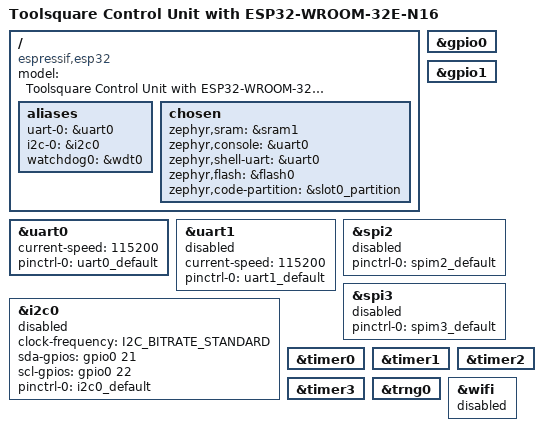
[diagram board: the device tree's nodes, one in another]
/dts-v1/;

#include <espressif/esp32/esp32_wroom_32ue_n16.dtsi>
#include "toolsquare-pinctrl.dtsi"
#include <espressif/partitions_0x1000_amp.dtsi>

/ {
	model = "Toolsquare Control Unit with ESP32-WROOM-32E-N16";
	compatible = "espressif,esp32";

	aliases {
		uart-0 = &uart0;
		i2c-0 = &i2c0;
		watchdog0 = &wdt0;
		// sdhc0 = &sdhc1;
	};

	chosen {
		zephyr,sram = &sram1;
		zephyr,console = &uart0;
		zephyr,shell-uart = &uart0;
		zephyr,flash = &flash0;
		zephyr,code-partition = &slot0_partition;
		// zephyr,display = &ili9341;
		// zephyr,sdhc = &sdhc1;
		// zephyr,bt-hci = &esp32_bt_hci;
	};

	// mipi_dbi {
	// 	compatible = "zephyr,mipi-dbi-spi";
	// 	dc-gpios = <&gpio0 21 GPIO_ACTIVE_HIGH>;
	// 	reset-gpios = <&gpio0 18 GPIO_ACTIVE_LOW>;
	// 	spi-dev = <&spi3>;
	// 	write-only;
	// 	#address-cells = <1>;
	// 	#size-cells = <0>;

	// 	ili9341: ili9341@0 {
	// 		compatible = "ilitek,ili9341";
	// 		mipi-max-frequency = <25000000>;
	// 		reg = <0>;
	// 		pixel-format = <0>;
	// 		rotation = <0>;
	// 		width = <240>;
	// 		height = <320>;
	// 	};
	// };
};

&uart0 {
	status = "okay";
	current-speed = <115200>;
	pinctrl-0 = <&uart0_default>;
	pinctrl-names = "default";
};

&uart1 {
	status = "disabled";
	current-speed = <115200>;
	pinctrl-0 = <&uart1_default>;
	pinctrl-names = "default";
};

&gpio0 {
	status = "okay";

	// lcd-backlight {
	// 	gpio-hog;
	// 	gpios = <5 GPIO_ACTIVE_HIGH>;
	// 	output-low;
	// };
};

&gpio1 {
	status = "okay";
};

&i2c0 {
	status = "disabled";
	clock-frequency = <I2C_BITRATE_STANDARD>;
	sda-gpios = <&gpio0 21 GPIO_OPEN_DRAIN>;
	scl-gpios = <&gpio0 22 GPIO_OPEN_DRAIN>;
	pinctrl-0 = <&i2c0_default>;
	pinctrl-names = "default";
};

&spi2 {
	status = "disabled";
	#address-cells = <1>;
	#size-cells = <0>;
	pinctrl-0 = <&spim2_default>;
	pinctrl-names = "default";
};

&spi3 {
	status = "disabled";
	#address-cells = <1>;
	#size-cells = <0>;
	pinctrl-0 = <&spim3_default>;
	pinctrl-names = "default";
};


&timer0 {
	status = "okay";
};

&timer1 {
	status = "okay";
};

&timer2 {
	status = "okay";
};

&timer3 {
	status = "okay";
};

&trng0 {
	status = "okay";
};

&wifi {
	status = "disabled";
};
